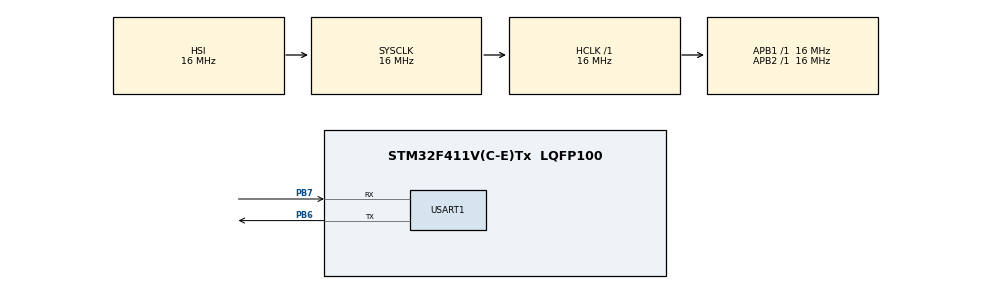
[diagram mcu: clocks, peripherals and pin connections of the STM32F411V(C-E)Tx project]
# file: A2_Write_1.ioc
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Mcu.Family=STM32F4
Mcu.Name=STM32F411V(C-E)Tx
Mcu.Package=LQFP100
NVIC.PriorityGroup=NVIC_PRIORITYGROUP_4
NVIC.USART1_IRQn=true\:0\:0\:false\:false\:true\:true\:true
PB6.Mode=Asynchronous
PB6.Signal=USART1_TX
PB7.Mode=Asynchronous
PB7.Signal=USART1_RX
ProjectManager.HeapSize=0x200
ProjectManager.StackSize=0x400
ProjectManager.TargetToolchain=STM32CubeIDE
RCC.AHBFreq_Value=16000000
RCC.APB1Freq_Value=16000000
RCC.APB2Freq_Value=16000000
RCC.CortexFreq_Value=16000000
RCC.HSE_VALUE=25000000
RCC.HSI_VALUE=16000000
RCC.LSE_VALUE=32768
RCC.SYSCLKFreq_VALUE=16000000
RCC.VCOOutputFreq_Value=192000000
USART1.VirtualMode=VM_ASYNC
board=custom

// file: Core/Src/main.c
/* USER CODE BEGIN Header */
/**
  ******************************************************************************
  * @file           : main.c
  * @brief          : Main program body
  ******************************************************************************
  * @attention
  *
  * <h2><center>&copy; Copyright (c) 2020 STMicroelectronics.
  * All rights reserved.</center></h2>
  *
  * This software component is licensed by ST under BSD 3-Clause license,
  * the "License"; You may not use this file except in compliance with the
  * License. You may obtain a copy of the License at:
  *                        opensource.org/licenses/BSD-3-Clause
  *
  ******************************************************************************
  */
/* USER CODE END Header */

#include "main.h"

/* USER CODE BEGIN Includes */
#include "stdio.h"
/* USER CODE END Includes */

UART_HandleTypeDef huart1;

/* USER CODE BEGIN PV */

volatile uint8_t char_received; // flag to indicate that a character was received from the UART
volatile uint8_t received_byte; // the byte that was received from the UART
uint8_t thebuffer[11];          // the buffer to hold the UART input
uint8_t writepos = 0;           // index where next UART received byte will be written
int16_t num1;                   // first number extracted from input buffer
int16_t num2;                   // second number extracted from input buffer
uint8_t opcode;                 // numeric code op operation to perform (1 = addition, 2 = subtraction, 3 = multiplication, 4 = division)
int32_t result;                 // result of calculation

/* USER CODE END PV */

void SystemClock_Config(void);
static void MX_GPIO_Init(void);
static void MX_USART1_UART_Init(void);

/* USER CODE BEGIN 0 */

/**
 * @brief Add a received byte to the input buffer, and test for terminating character
 *
 * This function will add the byte that is passed in the @rxbyte parameter to the
 * input buffer. The @inputbuffer is supplied as parameter to the function, as
 * well as a pointer to the position where the next byte must be placed in @inputbuffer.
 * the write position is passed as a pointer argument, @ptr_writepos, because the
 * function has to increment the write position after adding the byte to the input buffer,
 * and return it to the calling program.
 * The function must only allow writing into the buffer if the value pointed to by
 * @ptr_writepos is less than 11, because 11 is the maximum length of valid input
 * the function returns 1 if the received byte is the terminating character, otherwise
 * it returns 0.
 *
 * @param inputbuffer The array into which the received byte must be written
 * @param ptr_writepos Pointer to the position (index) where the received byte must
 *                     be written.
 * @param rxbyte The received byte
 *
 * @return 1 if a terminating characted was received. 0 otherwise
 */
uint8_t receive_byte(uint8_t* inputbuffer, uint8_t* ptr_writepos, uint8_t rxbyte)
{
   // pseudocode of what must be implemented:
   // if writepos < 11
   //    . write rxbyte into inputbuffer at index writepos
   //    . increment writepos
   //
   // if rxbyte is a '='
   //    return 1
   // else
   //    return 0
	if (*ptr_writepos < 11) {
		inputbuffer[*ptr_writepos] = rxbyte;
		*ptr_writepos += 1;
	}
	if (rxbyte == '=') {
		return 1;
	}
	else {
		return 0;
	}

}

/**
 * @brief Calculate the result for the provided arguments and opcode
 *
 * This function will perform the requested calculation and return the result
 *
 * @param num1 First number to use in the calculation.
 * @param num2 Second number to use in the calculation. If opcode equals 4 (division)
 *             then this parameter may not be 0.
 * @param opcode 1 = addition, 2 = subtraction, 3 = multiplication, 4 = division,
 *               for all other values of opcode, return zero
 *
 * @return The calculation result
 */
int32_t calc_result(int16_t num1, int16_t num2, uint8_t opcode)
{
	int32_t result = 0;

	if (opcode == 1) { //addition
		result = num1 + num2;
	}
	else if (opcode == 2) { // subtraction
		result = num1 - num2;
	}
	else if (opcode == 3) { // multiplication
		result = num1 * num2;
	}
	else if (opcode == 4) { // division
		if (num2 != 0) {
			result = num1 / num2;
		}
	}

	return result;
}

/**

* @brief Extract the two operands and operator from the input buffer
*
* This function will process the input buffer and extract the two operands (num1 and num2)
* from it as 16-bit signed integers. It will also determine which operation is required
* (+,-,x,/) and return a numeric code based on the operation.
* The operands as well as operation code are returned using pointers, supplied as
* function parameters. The function should return 1 if the input is correctly formatted
* and 0 otherwise.
*
* @param inputbuffer The array containing the input to process. maximum length is 11
* @param ptr_num1 Address where the first extracted number must be stored.
* @param ptr_num2 Address where the second extracted number must be stored.
* @param ptr_opcode Address where the operation must be stored.
*                   1 = addition, 2 = subtraction, 3 = multiplication, 4 = division
*
* @return 1 if the input is correctly formatted, 0 otherwise
*/
uint8_t process_input(uint8_t* inputbuffer, int16_t* ptr_num1, int16_t* ptr_num2, uint8_t* ptr_opcode)
{
  int16_t num1 = 0;
  int16_t num2 = 0;
  int ix = 0;
  int n1sign = 0;
  if (inputbuffer[0] == '-')
  {
     n1sign = 1;
     ix++;
  }
  while ((inputbuffer[ix] != '+') &&
         (inputbuffer[ix] != '-') &&
         (inputbuffer[ix] != 'x') &&
         (inputbuffer[ix] != '/'))
  {
     if ((inputbuffer[ix] >= '0') && (inputbuffer[ix] <= '9'))
     {
        if (num1 >= 9999)
           return 0;

        num1 *= 10;
        num1 += (inputbuffer[ix] - 48);
     }
     else
        return 0;

     ix++;
  }
  if (n1sign)
     num1 = -num1;

  switch (inputbuffer[ix])
  {
     case '+' : *ptr_opcode = 1; break;
     case '-' : *ptr_opcode = 2; break;
     case 'x' : *ptr_opcode = 3; break;
     case '/' : *ptr_opcode = 4; break;
  }
  ix++;

  while (inputbuffer[ix] != '=')
  {
     if ((inputbuffer[ix] >= '0') && (inputbuffer[ix] <= '9'))
     {
        if (num2 >= 9999)
           return 0;

        num2 *= 10;
        num2 += (inputbuffer[ix] - 48);
     }
     else
        return 0;

     ix++;
  }

  *ptr_num1 = num1;
  *ptr_num2 = num2;

 return 1;
}

void HAL_UART_RxCpltCallback(UART_HandleTypeDef *huart)
{
	char_received = 1;
	HAL_UART_Receive_IT(&huart1, &received_byte, 1);
}

/* USER CODE END 0 */

int main(void)
{

  /* MCU Configuration--------------------------------------------------------*/

  /* Reset of all peripherals, Initializes the Flash interface and the Systick. */
  HAL_Init();

  /* Configure the system clock */
  SystemClock_Config();

  /* Initialize all configured peripherals */
  MX_GPIO_Init();
  MX_USART1_UART_Init();
  /* USER CODE BEGIN 2 */

  HAL_UART_Receive_IT(&huart1, &received_byte, 1);
  /* USER CODE END 2 */

  /* Infinite loop */
  /* USER CODE BEGIN WHILE */
  while (1)
  {

	   if (char_received)
	   {
	      if (receive_byte(thebuffer, &writepos, received_byte) == 1)
	      {
	          if (process_input(thebuffer, &num1, &num2, &opcode) == 1)
	          {
	              if ((opcode == 4) && (num2 == 0))
	              {
	                  // reply to UART with 'divide by zero'
	            	  HAL_UART_Transmit(&huart1, (uint8_t*)"divide by zero\n", 15, 10);
	              }
	              else
	              {
	                  result = calc_result(num1, num2, opcode);
	                  // output result to UART
	                  char outstr[16];
	                  int outlen = sprintf(outstr,"%d\n", (int)result);
	                  HAL_UART_Transmit(&huart1, (uint8_t*) outstr, outlen, 10);

	              }
	          }
	          else
	          {
	              // reply to UART with 'invalid input'
	        	  HAL_UART_Transmit(&huart1, (uint8_t*) "invalid input\n", 14, 10);
	          }
	          writepos = 0; // reset write index, ready for next input
	      }
	      char_received = 0;
	   }

    /* USER CODE END WHILE */

  }
}

void SystemClock_Config(void)
{
  RCC_OscInitTypeDef RCC_OscInitStruct = {0};
  RCC_ClkInitTypeDef RCC_ClkInitStruct = {0};

  /** Configure the main internal regulator output voltage
  */
  __HAL_RCC_PWR_CLK_ENABLE();
  __HAL_PWR_VOLTAGESCALING_CONFIG(PWR_REGULATOR_VOLTAGE_SCALE1);
  /** Initializes the CPU, AHB and APB busses clocks
  */
  RCC_OscInitStruct.OscillatorType = RCC_OSCILLATORTYPE_HSI;
  RCC_OscInitStruct.HSIState = RCC_HSI_ON;
  RCC_OscInitStruct.HSICalibrationValue = RCC_HSICALIBRATION_DEFAULT;
  RCC_OscInitStruct.PLL.PLLState = RCC_PLL_NONE;
  if (HAL_RCC_OscConfig(&RCC_OscInitStruct) != HAL_OK)
  {
    Error_Handler();
  }
  /** Initializes the CPU, AHB and APB busses clocks
  */
  RCC_ClkInitStruct.ClockType = RCC_CLOCKTYPE_HCLK|RCC_CLOCKTYPE_SYSCLK
                              |RCC_CLOCKTYPE_PCLK1|RCC_CLOCKTYPE_PCLK2;
  RCC_ClkInitStruct.SYSCLKSource = RCC_SYSCLKSOURCE_HSI;
  RCC_ClkInitStruct.AHBCLKDivider = RCC_SYSCLK_DIV1;
  RCC_ClkInitStruct.APB1CLKDivider = RCC_HCLK_DIV1;
  RCC_ClkInitStruct.APB2CLKDivider = RCC_HCLK_DIV1;

  if (HAL_RCC_ClockConfig(&RCC_ClkInitStruct, FLASH_LATENCY_0) != HAL_OK)
  {
    Error_Handler();
  }
}

static void MX_USART1_UART_Init(void)
{

  huart1.Instance = USART1;
  huart1.Init.BaudRate = 115200;
  huart1.Init.WordLength = UART_WORDLENGTH_8B;
  huart1.Init.StopBits = UART_STOPBITS_1;
  huart1.Init.Parity = UART_PARITY_NONE;
  huart1.Init.Mode = UART_MODE_TX_RX;
  huart1.Init.HwFlowCtl = UART_HWCONTROL_NONE;
  huart1.Init.OverSampling = UART_OVERSAMPLING_16;
  if (HAL_UART_Init(&huart1) != HAL_OK)
  {
    Error_Handler();
  }

}

static void MX_GPIO_Init(void)
{

  /* GPIO Ports Clock Enable */
  __HAL_RCC_GPIOB_CLK_ENABLE();

}

void Error_Handler(void)
{
}

/************************ (C) COPYRIGHT STMicroelectronics *****END OF FILE****/
